# apollo4p register map
Vendor: Ambiq Micro; Series: Apollo; File version: 1.0
CPU: CM4 r1p0, little endian, MPU, FPU, I-cache, D-cache, VTOR, ITCM, DTCM, 3 interrupt priority bits, 0 interrupts
Registers are 32-bit, read-write, reset 0x0 unless marked. A register's access mark holds for its fields unless they carry their own. Offsets are from the block's base; [hi:lo] are bit positions; {n}, {i} and the like mark numbered series; 'fields as' and 'values as' point back to an identical list.

## DSP — DSP Control Interface
Base 0x40100000
{0x40+4i} MUTEX{i} (i=0..7)
  [2:0] MUTEX{i} — Mutex Value (000=resource free, 001=CPU owns mutex, 010=DSP0 owns mutex, 100=DSP1 owns mutex)
    0=NONE (Mutex is free); 1=CPU (CPU Owns Mutex); 2=DSP0 (DSP0 Owns Mutex); 4=DSP1 (DSP1 Owns Mutex); 6=CLEAR (Clear Mutex (conditional)); 7=SET (Set Mutex (conditional))
0x80 CPUMBINTSET — CPU Mailbox Interrupt Set
  [31:0] CPUMBINTSET — CPU Mailbox interrupt Set. The corresponding data bit will set the interrupt.
0x84 CPUMBINTCLR — CPU Mailbox Interrupt Clear
  [31:0] CPUMBINTCLR — CPU Mailbox interrupt Clear. The corresponding data bit will clear the interrupt.
0x88 CPUMBINTSTAT — CPU Mailbox Interrupt Status
  [31:0] CPUMBINTSTAT — CPU CPU Mailbox interrupt status
0x8C CPUCPUMBDATA — CPU CPU Mailbox Data
  [31:0] CPUCPUMBDATA — CPU CPU Mailbox data
0x90 DSP0CPUMBDATA — DSP0 to CPU Mailbox Data
  [31:0] DSP0CPUMBDATA — DSP0 to CPU Mailbox data
0x94 DSP1CPUMBDATA — DSP1 to CPU Mailbox Data
  [31:0] DSP1CPUMBDATA — DSP1 to CPU Mailbox data
0xA0 DSP0MBINTSET — DSP0 Mailbox Interrupt Set
  [31:0] DSP0MBINTSET — DSP0 Mailbox interrupt Set. The corresponding data bit will set the interrupt.
0xA4 DSP0MBINTCLR — DSP0 Mailbox Interrupt Clear
  [31:0] DSP0MBINTCLR — DSP0 Mailbox interrupt Clear. The corresponding data bit will clear the interrupt.
0xA8 DSP0MBINTSTAT — DSP 0 Mailbox Interrupt Status
  [31:0] DSP0MBINTSTAT — DSP 0 CPU Mailbox interrupt
0xAC CPUDSP0MBDATA — CPU to DSP 0 Mailbox Data
  [31:0] CPUDSP0MBDATA — DSP 0 CPU Mailbox data
0xB0 DSP0DSP0MBDATA — DSP0 to DSP 0 Mailbox Data
  [31:0] DSP0DSP0MBDATA — DSP0 to DSP 0 Mailbox data
0xB4 DSP1DSP0MBDATA — DSP1 to DSP 0 Mailbox Data
  [31:0] DSP1DSP0MBDATA — DSP1 to DSP 0 Mailbox data
0xC0 DSP1MBINTSET — DSP1 Mailbox Interrupt Set
  [31:0] DSP1MBINTSET — DSP1 Mailbox interrupt Set. The corresponding data bit will set the interrupt.
0xC4 DSP1MBINTCLR — DSP1 Mailbox Interrupt Clear
  [31:0] DSP1MBINTCLR — DSP1 Mailbox interrupt Clear. The corresponding data bit will clear the interrupt.
0xC8 DSP1MBINTSTAT — DSP 1 Mailbox Interrupt Status
  [31:0] DSP1MBINTSTAT — DSP 1 CPU Mailbox interrupt
0xCC CPUDSP1MBDATA — CPU to DSP 1 Mailbox Data
  [31:0] CPUDSP1MBDATA — DSP 1 CPU Mailbox data
0xD0 DSP0DSP1MBDATA — DSP0 to DSP 1 Mailbox Data
  [31:0] DSP0DSP1MBDATA — DSP0 to DSP 1 Mailbox data
0xD4 DSP1DSP1MBDATA — DSP1 to DSP 1 Mailbox Data
  [31:0] DSP1DSP1MBDATA — DSP1 to DSP 1 Mailbox data
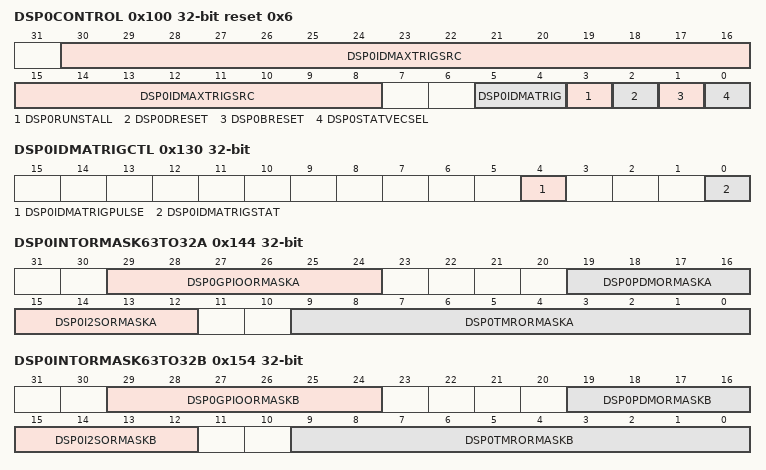
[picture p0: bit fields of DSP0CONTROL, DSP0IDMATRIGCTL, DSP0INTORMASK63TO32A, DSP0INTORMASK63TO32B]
0x100 DSP0CONTROL reset 0x6 — DSP 0 control settings
  [30:8] DSP0IDMAXTRIGSRC — DSP 0 IDMA Cross Trigger Source. All enabled sources are ANDed to generate a trigger enable. Bit30-12:IRQ18-0 Bit11: IDMATRIGPULSE, Bit10: DSP Timer1, Bit9: DSP Timer0, Bit8: alternate DSP iDMA trigger out
  [5:4] DSP0IDMATRIG — DSP 0 IDMA Trigger Control
    3=XTRIG (Trigger is disabled until a cross trigger pulse is asserted. This will allow another source (determined by the XTRIGSRC register) to allow the DMA descriptor chain to proceed.); 2=SSTEP (Trigger is disabled until a trigger pulse (PULSE in IDMATRIG register) is asserted. This will allow a single step in the DMA descriptor chain to be enabled until next completion.); 1=AON (Trigger is always enabled. With this set, any trigger out will immediately generate a trigger in); 0=DISABLE (Trigger is disabled. This will pause the iDMA indefinitely until enabled.)
  [3] DSP0RUNSTALL — DSP 0 RunStall. When asserted, DSP 0 will stall until bit is cleared.
  [2] DSP0DRESET — DSP0 DReset. This is the reset used for debug functionality like OCD/TRAX etc.
  [1] DSP0BRESET — DSP0 BReset. This is the reset used for Xtensa core. S/w must clear this reset to use Dsp.
  [0] DSP0STATVECSEL — DSP 0 StatVectorSel
0x104 DSP0RESETVEC — DSP 0 Reset Vector
  [31:0] DSP0RESETVEC — DSP 0 Reset Vector Address.
0x108 DSP0IRQMASK
  [22:0] DSP0IRQMASK
0x10C DSP0WAKEMASK — DSP 0 IRQ Wake Mask
  [22:0] DSP0WAKEMASK
0x110 DSP0RAWIRQSTAT31to0 — DSP 0 Raw IRQ31-0 Status
0x114 DSP0RAWIRQSTAT63to32 — DSP 0 Raw IRQ63-32 Status
0x118 DSP0RAWIRQSTAT95to64 — DSP 0 Raw IRQ95-64 Status
{0x118+4i} DSP0L{i}LVLINT (i=2..5) — DSP 0 L{i} Level Interrupt Mux
  [18:0] DSP0L{i}LVLINT
0x130 DSP0IDMATRIGCTL — DSP 0 IDMA Trigger Control and Status
  [4] DSP0IDMATRIGPULSE — DSP 0 iDMA Trigger Pulse - When written a '1', this will cause a single step enable (valid only when IDMATRIG is set to SSTEP)
  [0] DSP0IDMATRIGSTAT — DSP 0 iDMA Trigger Status
0x140 DSP0INTORMASK31TO0A — DSP0 Interrupt OR Mask A for IRQ31-0
  [31:0] DSP0INTMCUIOORMASKA — DSP0 MCU IO Interrupt OR Mask A
0x144 DSP0INTORMASK63TO32A — DSP0 Interrupt OR Mask A for IRQ63-32
  [29:24] DSP0GPIOORMASKA — DSP0 GPIO Interrupt OR Mask A
  [19:16] DSP0PDMORMASKA — DSP0 PDM Interrupt OR Mask A
  [15:12] DSP0I2SORMASKA — DSP0 I2S Interrupt OR Mask A
  [9:0] DSP0TMRORMASKA — DSP0 Timer Interrupt OR Mask A
0x148 DSP0INTORMASK95TO64A — DSP0 Interrupt OR Mask A for IRQ95-64
  [31:0] DSP0MBINTORMASKA — DSP0 Mailbox Interrupt OR Mask A
0x150 DSP0INTORMASK31to0B — DSP0 Interrupt OR Mask B for IRQ31-0
  [31:0] DSP0INTMCUIOORMASKB — DSP0 MCU IO Interrupt OR Mask B
0x154 DSP0INTORMASK63TO32B — DSP0 Interrupt OR Mask A for IRQ63-32
  [29:24] DSP0GPIOORMASKB — DSP0 GPIO Interrupt OR Mask B
  [19:16] DSP0PDMORMASKB — DSP0 PDM Interrupt OR Mask B
  [15:12] DSP0I2SORMASKB — DSP0 I2S Interrupt OR Mask B
  [9:0] DSP0TMRORMASKB — DSP0 Timer Interrupt OR Mask B
0x158 DSP0INTORMASK95TO64B — DSP0 Interrupt OR Mask B for IRQ95-64
  [31:0] DSP0MBINTORMASKB — DSP0 Mailbox Interrupt OR Mask B
0x160 DSP0INTENIRQ31TO0 — DSP0 INT Enable for IRQ31-0
0x164 DSP0INTENIRQ63TO32 — DSP0 INT Enable for IRQ63-32
0x168 DSP0INTENIRQ95TO64 — DSP0 INT Enable for IRQ95-64
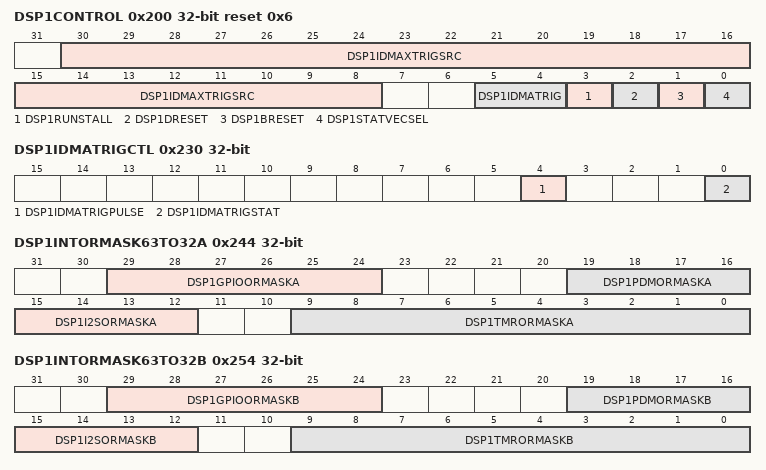
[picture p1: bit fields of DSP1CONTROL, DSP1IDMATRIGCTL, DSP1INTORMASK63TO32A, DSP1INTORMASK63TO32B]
0x200 DSP1CONTROL reset 0x6 — DSP 1 control settings
  [30:8] DSP1IDMAXTRIGSRC — DSP 1 IDMA Cross Trigger Source. All enabled sources are ANDed to generate a trigger enable. Bit30-12:IRQ18-0 Bit11: IDMATRIGPULSE, Bit10: DSP Timer1, Bit9: DSP Timer0, Bit8: alternate DSP iDMA trigger out
  [5:4] DSP1IDMATRIG — DSP 1 IDMA Trigger Control
    values as DSP0CONTROL.DSP0IDMATRIG
  [3] DSP1RUNSTALL — DSP 1 RunStall. When asserted, DSP 1 will stall until bit is cleared.
  [2] DSP1DRESET — DSP1 DReset. This is the reset used for debug functionality like OCD/TRAX etc.
  [1] DSP1BRESET — DSP1 BReset. This is the reset used for Xtensa core. S/w must clear this reset to use Dsp.
  [0] DSP1STATVECSEL — DSP 1 StatVectorSel
0x204 DSP1RESETVEC — DSP 1 Reset Vector
  [31:0] DSP1RESETVEC — DSP 1 Reset Vector Address.
0x208 DSP1IRQMASK
  [22:0] DSP1IRQMASK
0x20C DSP1WAKEMASK — DSP 1 IRQ Wake Mask
  [22:0] DSP1WAKEMASK
0x210 DSP1RAWIRQSTAT31to0 — DSP 1 Raw IRQ31-0 Status
0x214 DSP1RAWIRQSTAT63to32 — DSP 1 Raw IRQ63-32 Status
0x218 DSP1RAWIRQSTAT95to64 — DSP 1 Raw IRQ95-64 Status
{0x218+4i} DSP1L{i}LVLINT (i=2..5) — DSP 1 L{i} Level Interrupt Mux
  [18:0] DSP1L{i}LVLINT
0x230 DSP1IDMATRIGCTL — DSP 1 IDMA Trigger Control and Status
  [4] DSP1IDMATRIGPULSE — DSP 1 iDMA Trigger Pulse - When written a '1', this will cause a single step enable (valid only when IDMATRIG is set to SSTEP)
  [0] DSP1IDMATRIGSTAT — DSP 1 iDMA Trigger Status
0x240 DSP1INTORMASK31TO0A — DSP1 Interrupt OR Mask A for IRQ31-0
  [31:0] DSP1INTMCUIOORMASKA — DSP1 MCU IO Interrupt OR Mask A
0x244 DSP1INTORMASK63TO32A — DSP1 Interrupt OR Mask A for IRQ63-32
  [29:24] DSP1GPIOORMASKA — DSP1 GPIO Interrupt OR Mask A
  [19:16] DSP1PDMORMASKA — DSP1 PDM Interrupt OR Mask A
  [15:12] DSP1I2SORMASKA — DSP1 I2S Interrupt OR Mask A
  [9:0] DSP1TMRORMASKA — DSP1 Timer Interrupt OR Mask A
0x248 DSP1INTORMASK95TO64A — DSP1 Interrupt OR Mask A for IRQ95-64
  [31:0] DSP1MBINTORMASKA — DSP1 Mailbox Interrupt OR Mask A
0x250 DSP1INTORMASK31to0B — DSP1 Interrupt OR Mask B for IRQ31-0
  [31:0] DSP1INTMCUIOORMASKB — DSP1 MCU IO Interrupt OR Mask B
0x254 DSP1INTORMASK63TO32B — DSP1 Interrupt OR Mask A for IRQ63-32
  [29:24] DSP1GPIOORMASKB — DSP1 GPIO Interrupt OR Mask B
  [19:16] DSP1PDMORMASKB — DSP1 PDM Interrupt OR Mask B
  [15:12] DSP1I2SORMASKB — DSP1 I2S Interrupt OR Mask B
  [9:0] DSP1TMRORMASKB — DSP1 Timer Interrupt OR Mask B
0x258 DSP1INTORMASK95TO64B — DSP1 Interrupt OR Mask B for IRQ95-64
  [31:0] DSP1MBINTORMASKB — DSP1 Mailbox Interrupt OR Mask B
0x260 DSP1INTENIRQ31TO0 — DSP1 INT Enable for IRQ31-0
0x264 DSP1INTENIRQ63TO32 — DSP1 INT Enable for IRQ63-32
0x268 DSP1INTENIRQ95TO64 — DSP1 INT Enable for IRQ95-64
